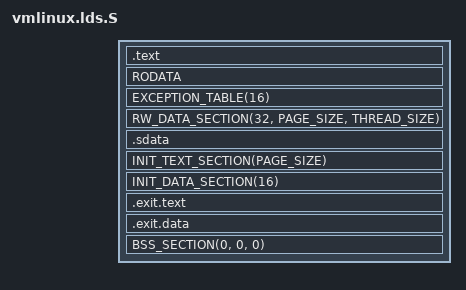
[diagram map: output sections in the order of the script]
/* Copyright Statement:
 *
 * This software/firmware and related documentation ("MediaTek Software") are
 * protected under relevant copyright laws. The information contained herein
 * is confidential and proprietary to MediaTek Inc. and/or its licensors.
 * Without the prior written permission of MediaTek inc. and/or its licensors,
 * any reproduction, modification, use or disclosure of MediaTek Software,
 * and information contained herein, in whole or in part, shall be strictly prohibited.
 *
 * MediaTek Inc. (C) 2010. All rights reserved.
 *
 * BY OPENING THIS FILE, RECEIVER HEREBY UNEQUIVOCALLY ACKNOWLEDGES AND AGREES
 * THAT THE SOFTWARE/FIRMWARE AND ITS DOCUMENTATIONS ("MEDIATEK SOFTWARE")
 * RECEIVED FROM MEDIATEK AND/OR ITS REPRESENTATIVES ARE PROVIDED TO RECEIVER ON
 * AN "AS-IS" BASIS ONLY. MEDIATEK EXPRESSLY DISCLAIMS ANY AND ALL WARRANTIES,
 * EXPRESS OR IMPLIED, INCLUDING BUT NOT LIMITED TO THE IMPLIED WARRANTIES OF
 * MERCHANTABILITY, FITNESS FOR A PARTICULAR PURPOSE OR NONINFRINGEMENT.
 * NEITHER DOES MEDIATEK PROVIDE ANY WARRANTY WHATSOEVER WITH RESPECT TO THE
 * SOFTWARE OF ANY THIRD PARTY WHICH MAY BE USED BY, INCORPORATED IN, OR
 * SUPPLIED WITH THE MEDIATEK SOFTWARE, AND RECEIVER AGREES TO LOOK ONLY TO SUCH
 * THIRD PARTY FOR ANY WARRANTY CLAIM RELATING THERETO. RECEIVER EXPRESSLY ACKNOWLEDGES
 * THAT IT IS RECEIVER'S SOLE RESPONSIBILITY TO OBTAIN FROM ANY THIRD PARTY ALL PROPER LICENSES
 * CONTAINED IN MEDIATEK SOFTWARE. MEDIATEK SHALL ALSO NOT BE RESPONSIBLE FOR ANY MEDIATEK
 * SOFTWARE RELEASES MADE TO RECEIVER'S SPECIFICATION OR TO CONFORM TO A PARTICULAR
 * STANDARD OR OPEN FORUM. RECEIVER'S SOLE AND EXCLUSIVE REMEDY AND MEDIATEK'S ENTIRE AND
 * CUMULATIVE LIABILITY WITH RESPECT TO THE MEDIATEK SOFTWARE RELEASED HEREUNDER WILL BE,
 * AT MEDIATEK'S OPTION, TO REVISE OR REPLACE THE MEDIATEK SOFTWARE AT ISSUE,
 * OR REFUND ANY SOFTWARE LICENSE FEES OR SERVICE CHARGE PAID BY RECEIVER TO
 * MEDIATEK FOR SUCH MEDIATEK SOFTWARE AT ISSUE.
 */

/*
 * arch/score/kernel/vmlinux.lds.S
 *
 * Score Processor version.
 *
 * Copyright (C) 2009 Sunplus Core Technology Co., Ltd.
 *  Chen Liqin <liqin.chen@sunplusct.com>
 *  Lennox Wu <lennox.wu@sunplusct.com>
 *
 * This program is free software; you can redistribute it and/or modify
 * it under the terms of the GNU General Public License as published by
 * the Free Software Foundation; either version 2 of the License, or
 * (at your option) any later version.
 *
 * This program is distributed in the hope that it will be useful,
 * but WITHOUT ANY WARRANTY; without even the implied warranty of
 * MERCHANTABILITY or FITNESS FOR A PARTICULAR PURPOSE.  See the
 * GNU General Public License for more details.
 *
 * You should have received a copy of the GNU General Public License
 * along with this program; if not, see the file COPYING, or write
 * to the Free Software Foundation, Inc.,
 * 51 Franklin St, Fifth Floor, Boston, MA  02110-1301  USA
 */

#include <asm-generic/vmlinux.lds.h>
#include <asm/thread_info.h>
#include <asm/page.h>

OUTPUT_ARCH(score)
ENTRY(_stext)

jiffies = jiffies_64;

SECTIONS
{
	. = CONFIG_MEMORY_START + 0x2000;
	/* read-only */
	.text : {
		_text = .;	/* Text and read-only data */
		TEXT_TEXT
		SCHED_TEXT
		LOCK_TEXT
		KPROBES_TEXT
		*(.text.*)
		*(.fixup)
		. = ALIGN (4) ;
		_etext = .;	/* End of text section */
	}

	. = ALIGN(16);
	RODATA

	EXCEPTION_TABLE(16)

	RW_DATA_SECTION(32, PAGE_SIZE, THREAD_SIZE)

	/* We want the small data sections together, so single-instruction offsets
	   can access them all, and initialized data all before uninitialized, so
	   we can shorten the on-disk segment size.  */
	. = ALIGN(8);
	.sdata : {
		*(.sdata)
	}
	_edata =  .;			/* End of data section */

	/* will be freed after init */
	. = ALIGN(PAGE_SIZE);		/* Init code and data */
	__init_begin = .;

	INIT_TEXT_SECTION(PAGE_SIZE)
	INIT_DATA_SECTION(16)

	/* .exit.text is discarded at runtime, not link time, to deal with
	 * references from .rodata
	 */
	.exit.text : {
		EXIT_TEXT
	}
	.exit.data : {
		EXIT_DATA
	}
	. = ALIGN(PAGE_SIZE);
	__init_end = .;
	/* freed after init ends here */

	BSS_SECTION(0, 0, 0)
	_end = .;
}
